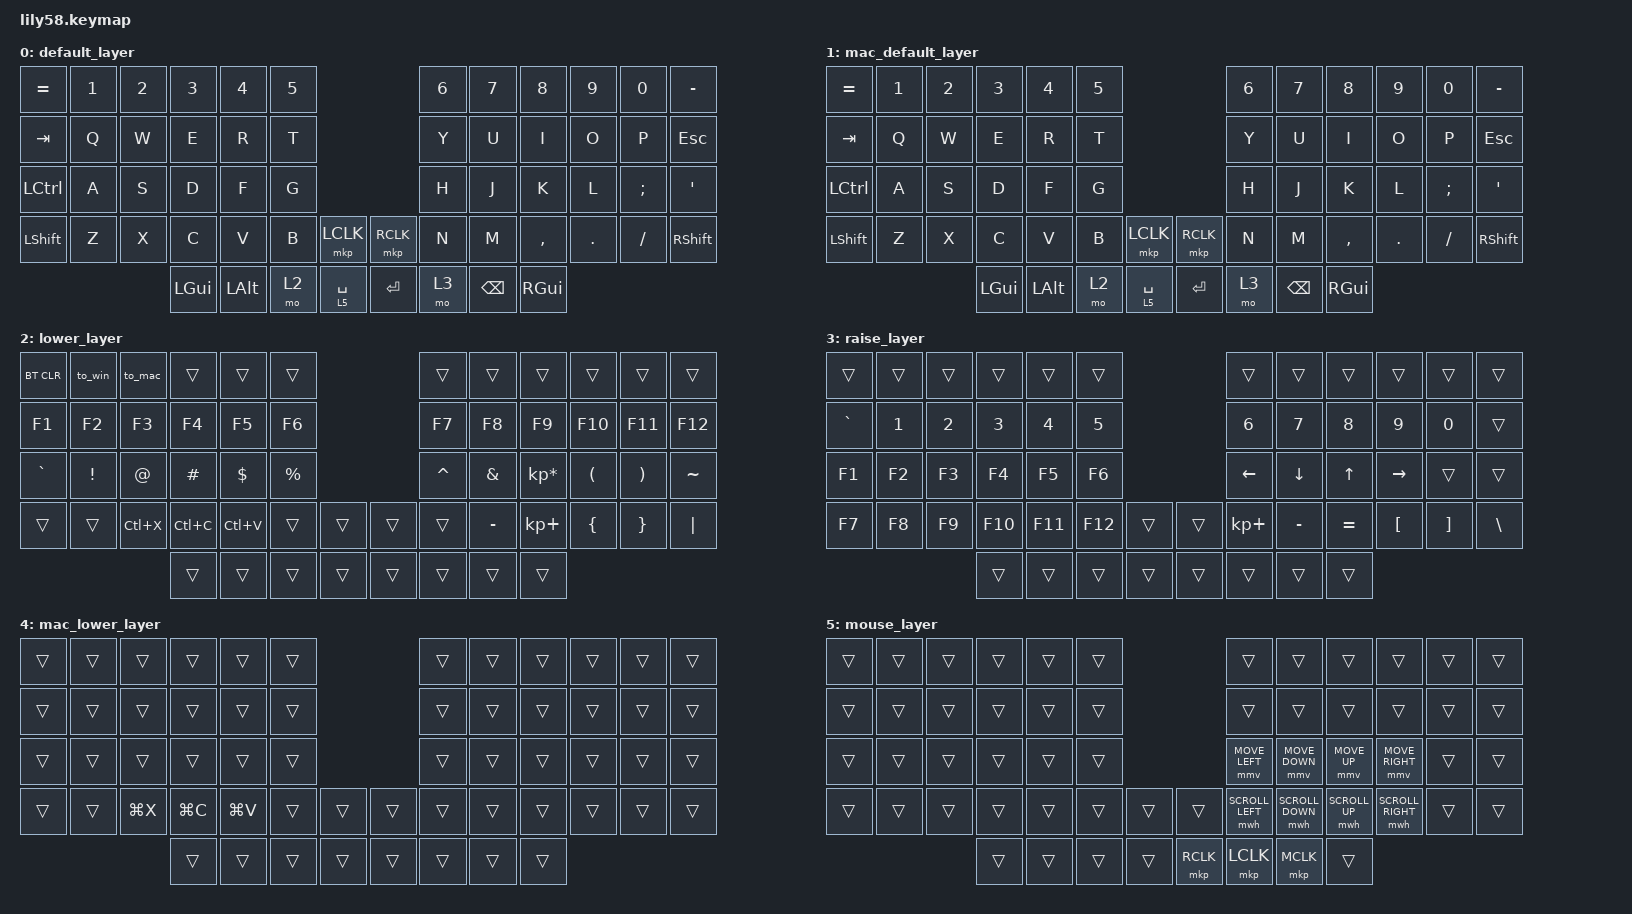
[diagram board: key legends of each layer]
/*
 * Copyright (c) 2020 The ZMK Contributors
 *
 * SPDX-License-Identifier: MIT
 */

#include <behaviors.dtsi>
#include <dt-bindings/zmk/bt.h>
#include <dt-bindings/zmk/ext_power.h>
#include <dt-bindings/zmk/keys.h>
#include <dt-bindings/zmk/mouse.h>

&mmv {
  time-to-max-speed-ms = <1500>;
  acceleration-exponent = <1>;
};

&mwh {
  time-to-max-speed-ms = <5000>;
  acceleration-exponent = <1>;
};

#define U_MOUSE_MOVE_MAX 1250
#define U_MOUSE_SCROLL_MAX 100

#undef MOVE_UP
#undef MOVE_DOWN
#undef MOVE_LEFT
#undef MOVE_RIGHT
#define MOVE_UP MOVE_VERT(-U_MOUSE_MOVE_MAX)
#define MOVE_DOWN MOVE_VERT(U_MOUSE_MOVE_MAX)
#define MOVE_LEFT MOVE_HOR(-U_MOUSE_MOVE_MAX)
#define MOVE_RIGHT MOVE_HOR(U_MOUSE_MOVE_MAX)

#undef SCROLL_UP
#undef SCROLL_DOWN
#undef SCROLL_LEFT
#undef SCROLL_RIGHT
#define SCROLL_UP SCROLL_VERT(U_MOUSE_SCROLL_MAX)
#define SCROLL_DOWN SCROLL_VERT(-U_MOUSE_SCROLL_MAX)
#define SCROLL_LEFT SCROLL_HOR(-U_MOUSE_SCROLL_MAX)
#define SCROLL_RIGHT SCROLL_HOR(U_MOUSE_SCROLL_MAX)


/ {
	keymap {
		compatible = "zmk,keymap";

		default_layer {  // 0
// ------------------------------------------------------------------------------------------------------------
// |   =   |  1  |  2  |  3   |  4   |  5   |                   |  6   |  7    |  8    |  9   |   0   |   -   |
// |  TAB  |  Q  |  W  |  E   |  R   |  T   |                   |  Y   |  U    |  I    |  O   |   P   |  ESC  |
// |  CTRL |  A  |  S  |  D   |  F   |  G   |                   |  H   |  J    |  K    |  L   |   ;   |   '   |
// | SHIFT |  Z  |  X  |  C   |  V   |  B   |  LCLK  |  | RCLK  |  N   |  M    |  ,    |  .   |   /   | SHIFT |
//                     | GUI  | ALT  | LOWER|  SPACE |  | ENTER | RAISE| BSPC  | GUI   |
			bindings = <
&kp EQUAL &kp N1 &kp N2 &kp N3   &kp N4   &kp N5                       &kp N6 &kp N7   &kp N8    &kp N9  &kp N0   &kp MINUS
&kp TAB   &kp Q  &kp W  &kp E    &kp R    &kp T                        &kp Y  &kp U    &kp I     &kp O   &kp P    &kp ESC
&kp LCTRL &kp A  &kp S  &kp D    &kp F    &kp G                        &kp H  &kp J    &kp K     &kp L   &kp SEMI &kp SQT
&kp LSHFT &kp Z  &kp X  &kp C    &kp V    &kp B  &mkp LCLK   &mkp RCLK &kp N  &kp M    &kp COMMA &kp DOT &kp FSLH &kp RSHFT
                        &kp LGUI &kp LALT &mo 2  &lt 5 SPACE &kp RET   &mo 3  &kp BSPC &kp RGUI
			>;

			sensor-bindings = <&inc_dec_kp C_VOL_UP C_VOL_DN>;
		};

		mac_default_layer {  // 1
// ------------------------------------------------------------------------------------------------------------
// |   =   |  1  |  2  |  3   |  4   |  5   |                   |  6   |  7    |  8    |  9   |   0   |   -   |
// |  TAB  |  Q  |  W  |  E   |  R   |  T   |                   |  Y   |  U    |  I    |  O   |   P   |  ESC  |
// |  CTRL |  A  |  S  |  D   |  F   |  G   |                   |  H   |  J    |  K    |  L   |   ;   |   '   |
// | SHIFT |  Z  |  X  |  C   |  V   |  B   |  LCLK  |  | RCLK  |  N   |  M    |  ,    |  .   |   /   | SHIFT |
//                     | GUI  | ALT  | LOWER|  SPACE |  | ENTER | RAISE| BSPC  | GUI   |
			bindings = <
&kp EQUAL &kp N1 &kp N2 &kp N3   &kp N4   &kp N5                       &kp N6 &kp N7   &kp N8    &kp N9  &kp N0   &kp MINUS
&kp TAB   &kp Q  &kp W  &kp E    &kp R    &kp T                        &kp Y  &kp U    &kp I     &kp O   &kp P    &kp ESC
&kp LCTRL &kp A  &kp S  &kp D    &kp F    &kp G                        &kp H  &kp J    &kp K     &kp L   &kp SEMI &kp SQT
&kp LSHFT &kp Z  &kp X  &kp C    &kp V    &kp B  &mkp LCLK   &mkp RCLK &kp N  &kp M    &kp COMMA &kp DOT &kp FSLH &kp RSHFT
                        &kp LGUI &kp LALT &mo 2  &lt 5 SPACE &kp RET   &mo 3  &kp BSPC &kp RGUI
			>;

			sensor-bindings = <&inc_dec_kp C_VOL_UP C_VOL_DN>;
		};

		lower_layer {  // 2
// ------------------------------------------------------------------------------------------------------------
// | BTCLR | BT1 | BT2 |      |      |      |                   |      |       |       |      |       |       |
// |  F1   |  F2 |  F3 |  F4  |  F5  |  F6  |                   |  F7  |  F8   |  F9   |  F10 |  F11  |  F12  |
// |   `   |  !  |  @  |  #   |  $   |  %   |                   |  ^   |  &    |  *    |  (   |   )   |   ~   |
// |       |     | CUT |  CPY | PSTE |      |        |  |       |      |  _    |  +    |  {   |   }   |  "|"  |
//                     |      |      |      |        |  |       |      |       |       |
			bindings = <
&bt BT_CLR &to_win  &to_mac   &trans     &trans       &trans                       &trans    &trans    &trans          &trans    &trans    &trans
&kp F1     &kp F2   &kp F3    &kp F4     &kp F5       &kp F6                       &kp F7    &kp F8    &kp F9          &kp F10   &kp F11   &kp F12
&kp GRAVE  &kp EXCL &kp AT    &kp HASH   &kp DOLLAR   &kp PRCNT                    &kp CARET &kp AMPS  &kp KP_MULTIPLY &kp LPAR  &kp RPAR  &kp TILDE
&trans     &trans   &kp LC(X) &kp LC(C)  &kp LC(V)    &trans    &trans   &trans    &trans    &kp MINUS &kp KP_PLUS     &kp LBRC  &kp RBRC  &kp PIPE
                                &trans     &trans       &trans    &trans   &trans    &trans    &trans    &trans
			>;

			sensor-bindings = <&inc_dec_kp C_VOL_UP C_VOL_DN>;
		};

		raise_layer {  // 3
// ------------------------------------------------------------------------------------------------------------
// |       |     |     |      |      |      |                   |      |       |       |      |       |       |
// |   `   |  1  |  2  |  3   |  4   |  5   |                   |  6   |   7   |   8   |  9   |   0   |       |
// |   F1  |  F2 |  F3 |  F4  |  F5  |  F6  |                   |  <-  |   v   |   ^   |  ->  |       |       |
// |   F7  |  F8 |  F9 |  F10 |  F11 |  F12 |        |  |       |  +   |   -   |   =   |  [   |   ]   |   \   |
//                     |      |      |      |        |  |       |      |       |       |
			bindings = <
&trans    &trans &trans &trans  &trans  &trans                       &trans      &trans    &trans    &trans    &trans    &trans
&kp GRAVE &kp N1 &kp N2 &kp N3  &kp N4  &kp N5                       &kp N6      &kp N7    &kp N8    &kp N9    &kp N0    &trans
&kp F1    &kp F2 &kp F3 &kp F4  &kp F5  &kp F6                       &kp LEFT    &kp DOWN  &kp UP    &kp RIGHT &trans    &trans
&kp F7    &kp F8 &kp F9 &kp F10 &kp F11 &kp F12   &trans   &trans    &kp KP_PLUS &kp MINUS &kp EQUAL &kp LBKT  &kp RBKT  &kp BSLH
                        &trans  &trans  &trans    &trans   &trans    &trans      &trans    &trans
			>;

			sensor-bindings = <&inc_dec_kp C_VOL_UP C_VOL_DN>;
		};

		mac_lower_layer {  // 4
// ------------------------------------------------------------------------------------------------------------
// |       |     |     |      |      |      |                   |      |       |       |      |       |       |
// |       |     |     |      |      |      |                   |      |       |       |      |       |       |
// |       |     |     |      |      |      |                   |      |       |       |      |       |       |
// |       |     | CUT |  CPY | PSTE |      |        |  |       |      |       |       |      |       |       |
//                     |      |      |      |        |  |       |      |       |       |
			bindings = <
&trans &trans &trans     &trans     &trans     &trans                      &trans      &trans    &trans    &trans    &trans    &trans
&trans &trans &trans     &trans     &trans     &trans                      &trans      &trans    &trans    &trans    &trans    &trans
&trans &trans &trans     &trans     &trans     &trans                      &trans      &trans    &trans    &trans    &trans    &trans
&trans &trans &kp LG(X)  &kp LG(C)  &kp LG(V)  &trans   &trans   &trans    &trans      &trans    &trans    &trans    &trans    &trans
                         &trans     &trans     &trans   &trans   &trans    &trans      &trans    &trans
			>;

			sensor-bindings = <&inc_dec_kp C_VOL_UP C_VOL_DN>;
		};

		mouse_layer {  // 5
// ------------------------------------------------------------------------------------------------------------
// |       |     |     |      |      |      |                   |      |       |       |      |       |       |
// |       |     |     |      |      |      |                   |      |       |       |      |       |       |
// |       |     |     |      |      |      |                   |      |       |       |      |       |       |
// |       |     |     |      |      |      |        |  |       |      |       |       |      |       |       |
//                     |      |      |      |        |  |       |      |       |       |
			bindings = <
&trans &trans &trans     &trans     &trans     &trans                       &trans           &trans           &trans         &trans            &trans    &trans
&trans &trans &trans     &trans     &trans     &trans                       &trans           &trans           &trans         &trans            &trans    &trans
&trans &trans &trans     &trans     &trans     &trans                       &mmv MOVE_LEFT   &mmv MOVE_DOWN   &mmv MOVE_UP   &mmv MOVE_RIGHT   &trans    &trans
&trans &trans &trans     &trans     &trans     &trans   &trans    &trans    &mwh SCROLL_LEFT &mwh SCROLL_DOWN &mwh SCROLL_UP &mwh SCROLL_RIGHT &trans    &trans
                         &trans     &trans     &trans   &trans    &mkp RCLK &mkp LCLK        &mkp MCLK        &trans
			>;

			sensor-bindings = <&inc_dec_kp C_VOL_UP C_VOL_DN>;
		};

	};

    conditional_layers {
        compatible = "zmk,conditional-layers";
        mac_lower_override {
            if-layers = <1 2>;
            then-layer = <4>;
        };
    };

	macros {
		ZMK_MACRO(to_win,
            wait-ms = <0>;
            tap-ms = <0>;
			bindings = <&bt BT_SEL 0 &to 0>;
		)

		ZMK_MACRO(to_mac,
            wait-ms = <0>;
            tap-ms = <0>;
			bindings = <&bt BT_SEL 1 &to 1>;
		)
	};
};
